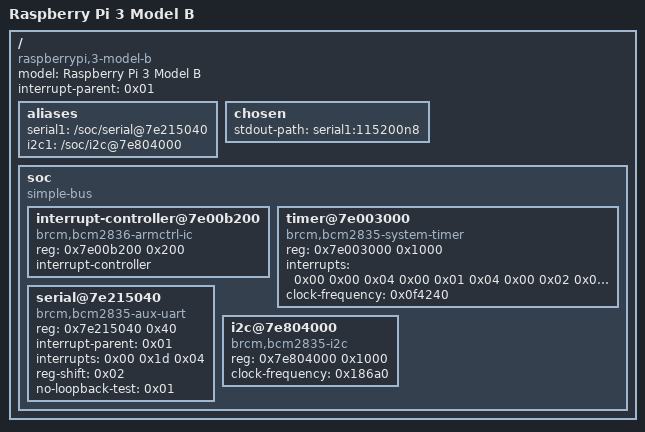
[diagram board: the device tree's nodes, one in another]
/*
 * Raspberry Pi 3B DTB for the local PCA9685 gimbal demo image.
 *
 * SPDX-License-Identifier: GPL-2.0-only
 */

/dts-v1/;

/memreserve/ 0x0000000000000000 0x0000000000001000;
/ {
	compatible = "raspberrypi,3-model-b\0brcm,bcm2837";
	model = "Raspberry Pi 3 Model B";
	interrupt-parent = <0x01>;
	#address-cells = <0x01>;
	#size-cells = <0x01>;

	aliases {
		serial1 = "/soc/serial@7e215040";
		i2c1 = "/soc/i2c@7e804000";
	};

	chosen {
		stdout-path = "serial1:115200n8";
	};

	soc {
		compatible = "simple-bus";
		#address-cells = <0x01>;
		#size-cells = <0x01>;
		ranges = <0x7e000000 0x3f000000 0x1000000 0x40000000 0x40000000 0x1000>;

		interrupt-controller@7e00b200 {
			compatible = "brcm,bcm2836-armctrl-ic";
			reg = <0x7e00b200 0x200>;
			interrupt-controller;
			#interrupt-cells = <0x03>;
			phandle = <0x01>;
		};

		timer@7e003000 {
			compatible = "brcm,bcm2835-system-timer";
			reg = <0x7e003000 0x1000>;
			interrupts = <0x00 0x00 0x04 0x00 0x01 0x04 0x00 0x02 0x04 0x00 0x03 0x04>;
			clock-frequency = <0x0f4240>;
		};

		serial@7e215040 {
			compatible = "brcm,bcm2835-aux-uart", "ns16550";
			reg = <0x7e215040 0x40>;
			interrupt-parent = <0x01>;
			interrupts = <0x00 0x1d 0x04>;
			reg-shift = <0x02>;
			no-loopback-test = <0x01>;
			status = "okay";
		};

		i2c@7e804000 {
			compatible = "brcm,bcm2835-i2c";
			reg = <0x7e804000 0x1000>;
			#address-cells = <0x01>;
			#size-cells = <0x00>;
			clock-frequency = <0x186a0>;
			status = "okay";
		};
	};
};
